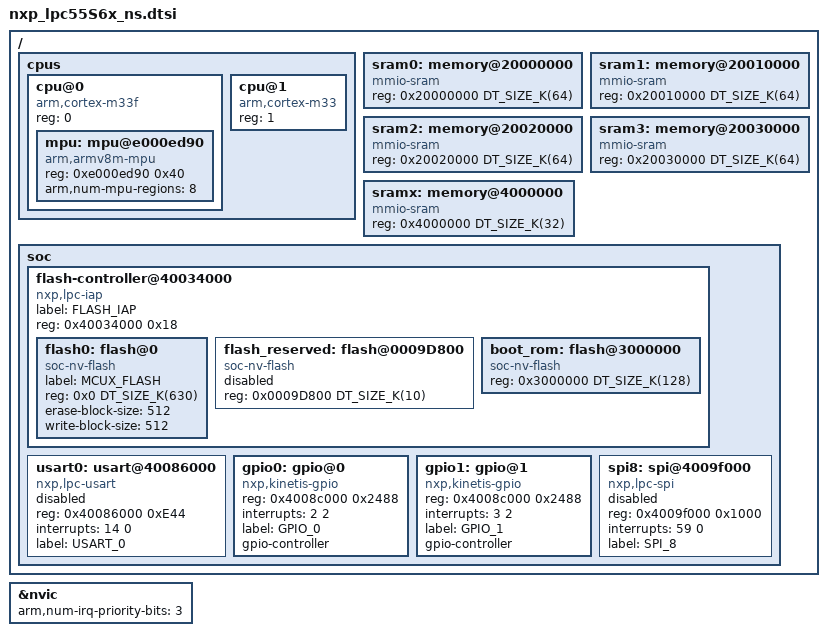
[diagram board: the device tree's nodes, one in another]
/*
 * Copyright (c) 2019, NXP
 *
 * SPDX-License-Identifier: Apache-2.0
 */

#include <mem.h>
#include <arm/armv8-m.dtsi>
#include <dt-bindings/gpio/gpio.h>

/ {
	cpus {
		#address-cells = <1>;
		#size-cells = <0>;

		cpu@0 {
			compatible = "arm,cortex-m33f";
			reg = <0>;
			#address-cells = <1>;
			#size-cells = <1>;

			mpu: mpu@e000ed90 {
				compatible = "arm,armv8m-mpu";
				reg = <0xe000ed90 0x40>;
				arm,num-mpu-regions = <8>;
			};
		};
		cpu@1 {
			compatible = "arm,cortex-m33";
			reg = <1>;
		};
	};

	sram0:memory@20000000 {
		compatible = "mmio-sram";
		reg = <0x20000000 DT_SIZE_K(64)>;
	};

	sram1:memory@20010000 {
		compatible = "mmio-sram";
		reg = <0x20010000 DT_SIZE_K(64)>;
	};

	sram2:memory@20020000 {
		compatible = "mmio-sram";
		reg = <0x20020000 DT_SIZE_K(64)>;
	};

	sram3:memory@20030000 {
		compatible = "mmio-sram";
		reg = <0x20030000 DT_SIZE_K(64)>;
	};

	sramx:memory@4000000{
		/* Conencted to USB bus*/
		compatible = "mmio-sram";
		reg = <0x4000000 DT_SIZE_K(32)>;
	};

	sramx:memory@4000000{
		/* connected to code bus */
		compatible = "mmio-sram";
		reg = <0x4000000 DT_SIZE_K(32)>;
	};

	soc {

		flash-controller@40034000 {
			compatible = "nxp,lpc-iap";
			label = "FLASH_IAP";
			reg = <0x40034000 0x18>;
			#address-cells = <1>;
			#size-cells = <1>;

			flash0: flash@0 {
				compatible = "soc-nv-flash";
				label = "MCUX_FLASH";
				reg = <0x0 DT_SIZE_K(630)>;
				erase-block-size = <512>;
				write-block-size = <512>;
			};

			flash_reserved:flash@0009D800 {
				compatible = "soc-nv-flash";
				reg = <0x0009D800 DT_SIZE_K(10)>;
				status = "disabled";
			};

			boot_rom:flash@3000000 {
				compatible = "soc-nv-flash";
				reg = <0x3000000 DT_SIZE_K(128)>;
			};
		};


		usart0:usart@40086000 {
			compatible = "nxp,lpc-usart";
			reg = <0x40086000 0xE44>;
			interrupts = <14 0>;
			label = "USART_0";
			status = "disabled";
		};

		gpio0: gpio@0 {
			compatible = "nxp,kinetis-gpio";
			reg = <0x4008c000 0x2488>;
			interrupts = <2 2>;
			label = "GPIO_0";
			gpio-controller;
			#gpio-cells = <2>;
		};

		gpio1: gpio@1 {
			compatible = "nxp,kinetis-gpio";
			reg = <0x4008c000 0x2488>;
			interrupts = <3 2>;
			label = "GPIO_1";
			gpio-controller;
			#gpio-cells = <2>;
		};

		spi8: spi@4009f000 {
			compatible = "nxp,lpc-spi";
			reg = <0x4009f000 0x1000>;
			interrupts = <59 0>;
			label = "SPI_8";
			status = "disabled";
			#address-cells = <1>;
			#size-cells = <0>;
		};
	};
};

&nvic {
	arm,num-irq-priority-bits = <3>;
};
